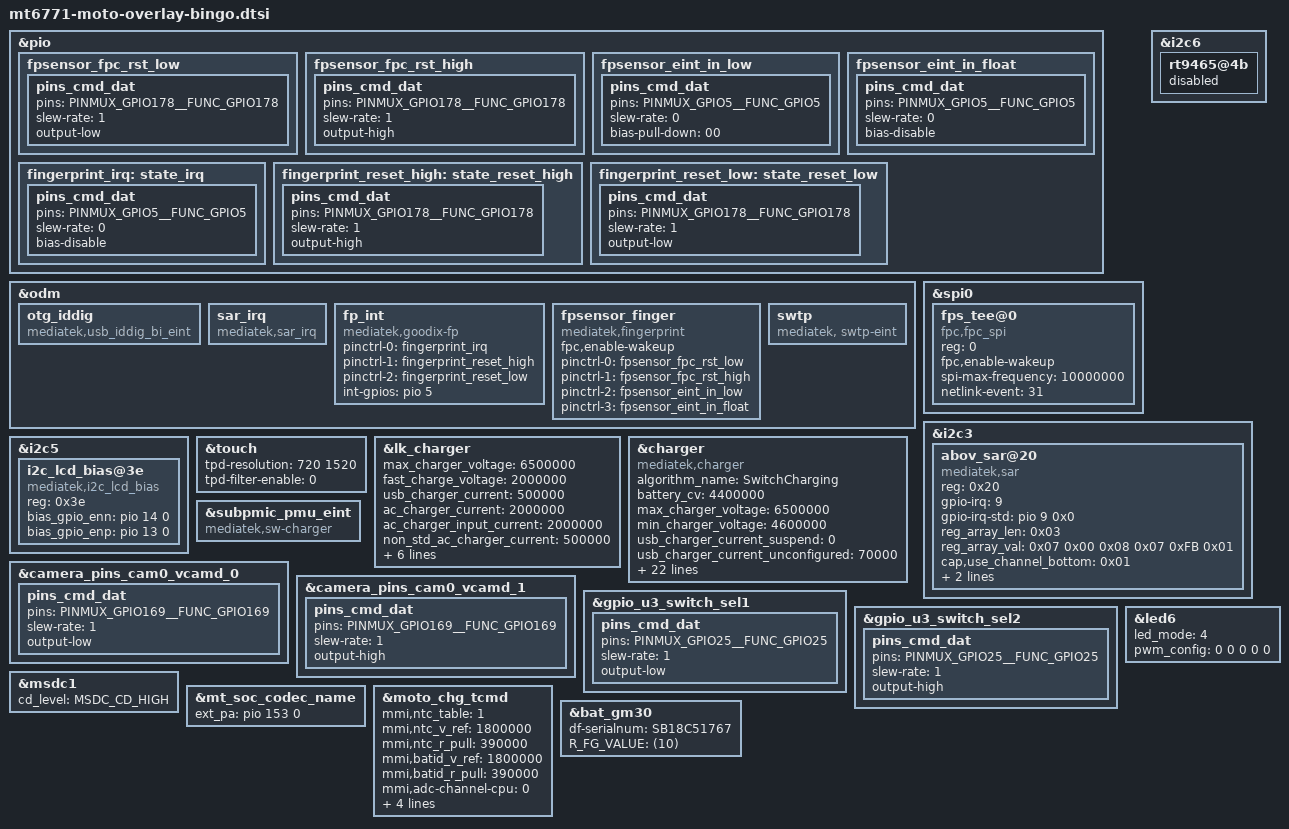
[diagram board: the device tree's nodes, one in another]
/* Copyright (c) 2019, Motorola Mobility Inc. All rights reserved.
 *
 * This program is free software; you can redistribute it and/or modify
 * it under the terms of the GNU General Public License version 2 and
 * only version 2 as published by the Free Software Foundation.
 *
 * This program is distributed in the hope that it will be useful,
 * but WITHOUT ANY WARRANTY; without even the implied warranty of
 * MERCHANTABILITY or FITNESS FOR A PARTICULAR PURPOSE.  See the
 * GNU General Public License for more details.
 */

#include "mt6771-moto-overlay.dtsi"
#include "mt6771-camera-sensor-moto-bingo.dtsi"
#include "bq2560x.dtsi"
#include "sgm37604a.dtsi"

&pio {
	fpsensor_fpc_rst_low: fpsensor_fpc_rst_low {
		pins_cmd_dat {
			pins = <PINMUX_GPIO178__FUNC_GPIO178>;
			slew-rate = <1>;
			output-low;
		};
	};

	fpsensor_fpc_rst_high: fpsensor_fpc_rst_high {
		pins_cmd_dat {
			pins = <PINMUX_GPIO178__FUNC_GPIO178>;
			slew-rate = <1>;
			output-high;
		};
	};

	fpsensor_eint_in_low: fpsensor_eint_in_low {
		pins_cmd_dat {
			pins = <PINMUX_GPIO5__FUNC_GPIO5>;
			slew-rate = <0>;
			bias-pull-down = <00>;
		};
	};

	fpsensor_eint_in_float: fpsensor_eint_in_float {
		pins_cmd_dat {
			pins = <PINMUX_GPIO5__FUNC_GPIO5>;
			slew-rate = <0>;
			bias-disable;
		};
	};

	fingerprint_irq: state_irq {
		pins_cmd_dat {
			pins = <PINMUX_GPIO5__FUNC_GPIO5>;
			slew-rate = <0>;
			bias-disable;
		};
	};

	fingerprint_reset_high: state_reset_high {
		pins_cmd_dat {
			pins = <PINMUX_GPIO178__FUNC_GPIO178>;
			slew-rate = <1>;
			output-high;
		};
	};

	fingerprint_reset_low: state_reset_low {
		pins_cmd_dat {
			pins = <PINMUX_GPIO178__FUNC_GPIO178>;
			slew-rate = <1>;
			output-low;
		};
	};
};

&odm {
	otg_iddig:otg_iddig  {
	compatible = "mediatek,usb_iddig_bi_eint";
	};
	sar_irq:sar_irq {
	compatible = "mediatek,sar_irq";
	};

	fp_int:fp_int{
		compatible = "mediatek,goodix-fp", "mediatek,fpsensor_fp_eint";
		pinctrl-names = "fingerprint_irq", "reset_high", "reset_low";
		pinctrl-0 = <&fingerprint_irq>;
		pinctrl-1 = <&fingerprint_reset_high>;
		pinctrl-2 = <&fingerprint_reset_low>;
		int-gpios = <&pio 5 0>;
		status = "okay";
	};

	fpsensor_finger:fpsensor_finger{
		compatible = "mediatek,fingerprint";
		fpc,enable-wakeup;
		pinctrl-names = "fpsensor_fpc_rst_low", "fpsensor_fpc_rst_high",
				"fpsensor_eint_in_low", "fpsensor_eint_in_float";
		pinctrl-0 = <&fpsensor_fpc_rst_low>;
		pinctrl-1 = <&fpsensor_fpc_rst_high>;
		pinctrl-2 = <&fpsensor_eint_in_low>;
		pinctrl-3 = <&fpsensor_eint_in_float>;
		status = "okay";
	};
	swtp: swtp {
		compatible = "mediatek, swtp-eint";
	};
};
&spi0 {
	#address-cells = <1>;
	#size-cells = <0>;
	fps_tee@0 {
		compatible = "fpc,fpc_spi", "goodix,goodix-fp";
		reg = <0>;
		fpc,enable-wakeup;
		spi-max-frequency = <10000000>;
		netlink-event = <31>;
		status = "okay";
	};
};

&i2c6 {
	rt9465@4b {
		status = "disabled";
	};
};

&i2c3 {
	abov_sar@20 {
	compatible = "mediatek,sar";
	reg = <0x20>;
	gpio-irq = <9>;
	gpio-irq-std = <&pio 9 0x0>;
	reg_array_len = <0x03>;
	reg_array_val = <0x07 0x00 0x08 0x07 0xFB 0x01>;
		cap,use_channel_bottom = <0x01>;
		cap,use_channel_top = <0x00>;
		label = "AbovCapSense";
		status = "okay";
	};
};

&i2c5 {
	i2c_lcd_bias@3e {
		compatible = "mediatek,i2c_lcd_bias";
		reg = <0x3e>;
		bias_gpio_enn = <&pio 14 0>;
		bias_gpio_enp = <&pio 13 0>;
		status = "okay";
	};
};

&touch {
	tpd-resolution = <720 1520>;
	tpd-filter-enable = <0>;
};
&lk_charger {
		max_charger_voltage = <6500000>;
		fast_charge_voltage = <2000000>;

		/* charging current */
		usb_charger_current = <500000>;
		ac_charger_current = <2000000>;
		ac_charger_input_current = <2000000>;
		non_std_ac_charger_current = <500000>;
		charging_host_charger_current = <1500000>;
		ta_ac_charger_current = <3000000>;
		pd_charger_current = <500000>;

		/* battery temperature protection */
		temp_t4_threshold = <50>;
		temp_t3_threshold = <45>;
		temp_t1_threshold = <0>;
};
&charger {
		compatible = "mediatek,charger";
		algorithm_name = "SwitchCharging";

		/* common */
		battery_cv = <4400000>;
		max_charger_voltage = <6500000>;
		min_charger_voltage = <4600000>;

		/* charging current */
		usb_charger_current_suspend = <0>;
		usb_charger_current_unconfigured = <70000>;
		usb_charger_current_configured = <500000>;
		usb_charger_current = <500000>;
		ac_charger_current = <2000000>;
		ac_charger_input_current = <2000000>;
		non_std_ac_charger_current = <500000>;
		charging_host_charger_current = <1500000>;
		apple_1_0a_charger_current = <650000>;
		apple_2_1a_charger_current = <800000>;
		ta_ac_charger_current = <2000000>;

		/* battery temperature protection */
		enable_min_charge_temperature;
		min_charge_temperature = <0>;
		min_charge_temperature_plus_x_degree = <6>;
		max_charge_temperature = <60>;
		max_charge_temperature_minus_x_degree = <57>;

		/*mmi config*/
		mmi,iterm-ma = <194>;
		mmi,mmi-temp-zones = <0 4200 776 0>,
				<10 4200 1940 776>,
				<15 0 1940 1940>,
				<45 4200 2000 2000>,
				<60 4200 1940 0>;
		mmi,enable-charging-limit;
		mmi,upper-limit-capacity = <75>;
		mmi,lower-limit-capacity = <60>;
		mmi,vfloat-comp-uv = <20000>;
};
&subpmic_pmu_eint {
	compatible = "mediatek,sw-charger";
};

&camera_pins_cam0_vcamd_0 {
	pins_cmd_dat {
		pins = <PINMUX_GPIO169__FUNC_GPIO169>;
		slew-rate = <1>;
		output-low;
	};
};
&camera_pins_cam0_vcamd_1 {
	pins_cmd_dat {
		pins = <PINMUX_GPIO169__FUNC_GPIO169>;
		slew-rate = <1>;
		output-high;
	};
};
&gpio_u3_switch_sel1 {
	pins_cmd_dat {
		pins = <PINMUX_GPIO25__FUNC_GPIO25>;
		slew-rate = <1>;
		output-low;
	};
};
&gpio_u3_switch_sel2 {
	pins_cmd_dat {
		pins = <PINMUX_GPIO25__FUNC_GPIO25>;
		slew-rate = <1>;
		output-high;
	};
};
&msdc1 {
	cd_level = /bits/ 8 <MSDC_CD_HIGH>;
};
&mt_soc_codec_name {
		ext_pa =  <&pio 153 0>;
};
&led6{
	led_mode = <4>;
	pwm_config = <0 0 0 0 0>;
};

&moto_chg_tcmd {
	status = "okay";

	mmi,ntc_table = <1>;
	mmi,ntc_v_ref = <1800000>;
	mmi,ntc_r_pull = <390000>;

	mmi,batid_v_ref = <1800000>;
	mmi,batid_r_pull = <390000>;

	mmi,adc-channel-cpu = <0>;
	mmi,adc-channel-charger = <2>;
	mmi,adc-channel-pa = <1>;
	mmi,adc-channel-batid = <3>;
	mmi,adc-channel-vbat = <100>;
};

&bat_gm30 {
	df-serialnum = "SB18C51767";
	R_FG_VALUE = <(10)>;    /* R_sense resistance.*/
};
